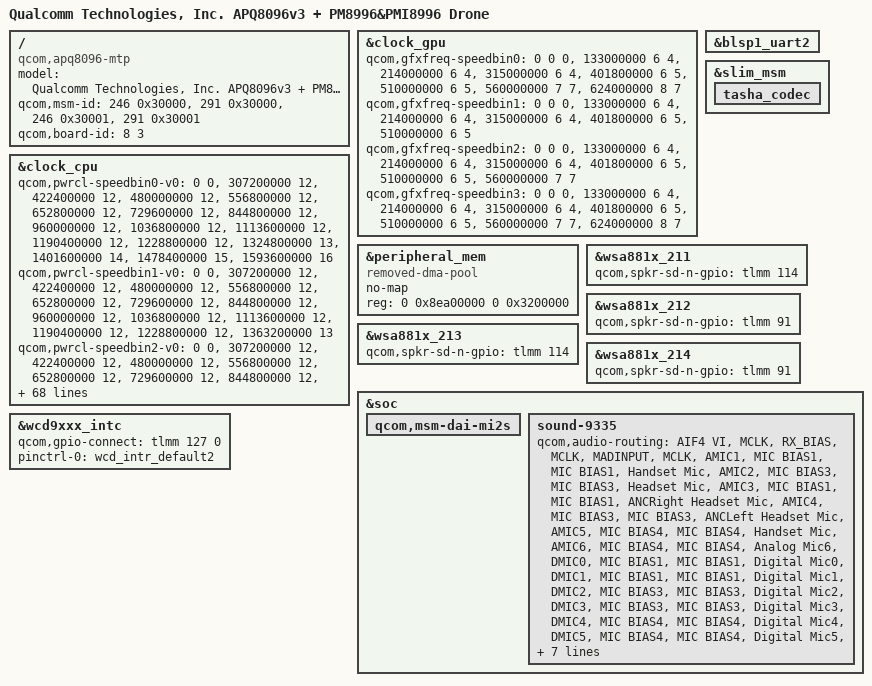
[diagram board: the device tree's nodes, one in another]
/* Copyright (c) 2016-2017, The Linux Foundation. All rights reserved.
 *
 * This program is free software; you can redistribute it and/or modify
 * it under the terms of the GNU General Public License version 2 and
 * only version 2 as published by the Free Software Foundation.
 *
 * This program is distributed in the hope that it will be useful,
 * but WITHOUT ANY WARRANTY; without even the implied warranty of
 * MERCHANTABILITY or FITNESS FOR A PARTICULAR PURPOSE.  See the
 * GNU General Public License for more details.
 */


/dts-v1/;

#include "apq8096-v3.dtsi"
#include "apq8096-drone.dtsi"
#include "msm8996-wsa881x.dtsi"

/ {
	model = "Qualcomm Technologies, Inc. APQ8096v3 + PM8996&PMI8996 Drone";
	compatible = "qcom,apq8096-mtp", "qcom,msm8996",
			"qcom,apq8096";
	qcom,msm-id = <246 0x30000>, <291 0x30000>,
			<246 0x30001>, <291 0x30001>;
	qcom,board-id = <8 3>;
};

&clock_gpu {
	qcom,gfxfreq-speedbin0 =
		<          0  0  0 >,
		<  133000000  6  4 >,
		<  214000000  6  4 >,
		<  315000000  6  4 >,
		<  401800000  6  5 >,
		<  510000000  6  5 >,
		<  560000000  7  7 >,
		<  624000000  8  7 >;
	qcom,gfxfreq-speedbin1 =
		<          0  0  0 >,
		<  133000000  6  4 >,
		<  214000000  6  4 >,
		<  315000000  6  4 >,
		<  401800000  6  5 >,
		<  510000000  6  5 >;
	qcom,gfxfreq-speedbin2 =
		<          0  0  0 >,
		<  133000000  6  4 >,
		<  214000000  6  4 >,
		<  315000000  6  4 >,
		<  401800000  6  5 >,
		<  510000000  6  5 >,
		<  560000000  7  7 >;
	qcom,gfxfreq-speedbin3 =
		<          0  0  0 >,
		<  133000000  6  4 >,
		<  214000000  6  4 >,
		<  315000000  6  4 >,
		<  401800000  6  5 >,
		<  510000000  6  5 >,
		<  560000000  7  7 >,
		<  624000000  8  7 >;
};


&clock_cpu {
	qcom,pwrcl-speedbin0-v0 =
		<          0  0 >,
		<  307200000 12 >,
		<  422400000 12 >,
		<  480000000 12 >,
		<  556800000 12 >,
		<  652800000 12 >,
		<  729600000 12 >,
		<  844800000 12 >,
		<  960000000 12 >,
		< 1036800000 12 >,
		< 1113600000 12 >,
		< 1190400000 12 >,
		< 1228800000 12 >,
		< 1324800000 13 >,
		< 1401600000 14 >,
		< 1478400000 15 >,
		< 1593600000 16 >;
	qcom,pwrcl-speedbin1-v0 =
		<          0  0 >,
		<  307200000 12 >,
		<  422400000 12 >,
		<  480000000 12 >,
		<  556800000 12 >,
		<  652800000 12 >,
		<  729600000 12 >,
		<  844800000 12 >,
		<  960000000 12 >,
		< 1036800000 12 >,
		< 1113600000 12 >,
		< 1190400000 12 >,
		< 1228800000 12 >,
		< 1363200000 13 >;
	qcom,pwrcl-speedbin2-v0 =
		<          0  0 >,
		<  307200000 12 >,
		<  422400000 12 >,
		<  480000000 12 >,
		<  556800000 12 >,
		<  652800000 12 >,
		<  729600000 12 >,
		<  844800000 12 >,
		<  960000000 12 >,
		< 1036800000 12 >,
		< 1113600000 12 >,
		< 1190400000 12 >,
		< 1228800000 12 >,
		< 1324800000 13 >,
		< 1401600000 14 >,
		< 1497600000 15 >;
	qcom,pwrcl-speedbin3-v0 =
		<          0  0 >,
		<  307200000 12 >,
		<  422400000 12 >,
		<  480000000 12 >,
		<  556800000 12 >,
		<  652800000 12 >,
		<  729600000 12 >,
		<  844800000 12 >,
		<  960000000 12 >,
		< 1036800000 12 >,
		< 1113600000 12 >,
		< 1190400000 12 >,
		< 1228800000 12 >,
		< 1324800000 13 >,
		< 1401600000 14 >,
		< 1478400000 15 >,
		< 1593600000 16 >;
	qcom,perfcl-speedbin0-v0 =
		<          0  0 >,
		<  307200000 13 >,
		<  403200000 13 >,
		<  480000000 13 >,
		<  556800000 13 >,
		<  652800000 13 >,
		<  729600000 13 >,
		<  806400000 13 >,
		<  883200000 13 >,
		<  940800000 13 >,
		< 1036800000 13 >,
		< 1113600000 13 >,
		< 1190400000 13 >,
		< 1248000000 13 >,
		< 1324800000 14 >,
		< 1401600000 15 >,
		< 1478400000 16 >,
		< 1555200000 17 >,
		< 1632000000 18 >,
		< 1708800000 19 >,
		< 1785600000 20 >,
		< 1824000000 21 >,
		< 1920000000 22 >,
		< 1996800000 23 >,
		< 2073600000 24 >,
		< 2150400000 25 >;
	qcom,perfcl-speedbin1-v0 =
		<          0  0 >,
		<  307200000 13 >,
		<  403200000 13 >,
		<  480000000 13 >,
		<  556800000 13 >,
		<  652800000 13 >,
		<  729600000 13 >,
		<  806400000 13 >,
		<  883200000 13 >,
		<  940800000 13 >,
		< 1036800000 13 >,
		< 1113600000 13 >,
		< 1190400000 13 >,
		< 1248000000 13 >,
		< 1324800000 14 >,
		< 1401600000 15 >,
		< 1478400000 16 >,
		< 1555200000 17 >,
		< 1632000000 18 >,
		< 1708800000 19 >,
		< 1785600000 20 >,
		< 1804800000 21 >;
	qcom,perfcl-speedbin2-v0 =
		<          0  0 >,
		<  307200000 13 >,
		<  403200000 13 >,
		<  480000000 13 >,
		<  556800000 13 >,
		<  652800000 13 >,
		<  729600000 13 >,
		<  806400000 13 >,
		<  883200000 13 >,
		<  940800000 13 >,
		< 1036800000 13 >,
		< 1113600000 13 >,
		< 1190400000 13 >,
		< 1248000000 13 >,
		< 1324800000 14 >,
		< 1401600000 15 >,
		< 1478400000 16 >,
		< 1555200000 17 >,
		< 1632000000 18 >,
		< 1708800000 19 >,
		< 1785600000 20 >,
		< 1804800000 21 >,
		< 1900800000 22 >;
	qcom,perfcl-speedbin3-v0 =
		<          0  0 >,
		<  307200000 13 >,
		<  403200000 13 >,
		<  480000000 13 >,
		<  556800000 13 >,
		<  652800000 13 >,
		<  729600000 13 >,
		<  806400000 13 >,
		<  883200000 13 >,
		<  940800000 13 >,
		< 1036800000 13 >,
		< 1113600000 13 >,
		< 1190400000 13 >,
		< 1248000000 13 >,
		< 1324800000 14 >,
		< 1401600000 15 >,
		< 1478400000 16 >,
		< 1555200000 17 >,
		< 1632000000 18 >,
		< 1708800000 19 >,
		< 1785600000 20 >,
		< 1804800000 21 >;
	qcom,cbf-speedbin0-v0 =
		<          0  0 >,
		<  307200000 13 >,
		<  384000000 13 >,
		<  460800000 13 >,
		<  537600000 13 >,
		<  595200000 13 >,
		<  672000000 13 >,
		<  748800000 13 >,
		<  825600000 13 >,
		<  902400000 13 >,
		<  979200000 13 >,
		< 1056000000 13 >,
		< 1132800000 13 >,
		< 1190400000 13 >,
		< 1228800000 14 >,
		< 1305600000 15 >,
		< 1382400000 16 >,
		< 1459200000 17 >,
		< 1536000000 18 >,
		< 1593600000 19 >;
	qcom,cbf-speedbin1-v0 =
		<          0  0 >,
		<  307200000 13 >,
		<  384000000 13 >,
		<  460800000 13 >,
		<  537600000 13 >,
		<  595200000 13 >,
		<  672000000 13 >,
		<  748800000 13 >,
		<  825600000 13 >,
		<  902400000 13 >,
		<  979200000 13 >,
		< 1056000000 13 >,
		< 1132800000 13 >,
		< 1190400000 13 >,
		< 1228800000 14 >,
		< 1305600000 15 >;
	qcom,cbf-speedbin2-v0 =
		<          0  0 >,
		<  307200000 13 >,
		<  384000000 13 >,
		<  460800000 13 >,
		<  537600000 13 >,
		<  595200000 13 >,
		<  672000000 13 >,
		<  748800000 13 >,
		<  825600000 13 >,
		<  902400000 13 >,
		<  979200000 13 >,
		< 1056000000 13 >,
		< 1132800000 13 >,
		< 1190400000 13 >,
		< 1228800000 14 >,
		< 1305600000 15 >;
	qcom,cbf-speedbin3-v0 =
		<          0  0 >,
		<  307200000 13 >,
		<  384000000 13 >,
		<  460800000 13 >,
		<  537600000 13 >,
		<  595200000 13 >,
		<  672000000 13 >,
		<  748800000 13 >,
		<  825600000 13 >,
		<  902400000 13 >,
		<  979200000 13 >,
		< 1056000000 13 >,
		< 1132800000 13 >,
		< 1190400000 13 >,
		< 1228800000 14 >,
		< 1305600000 15 >,
		< 1382400000 16 >,
		< 1459200000 17 >,
		< 1536000000 18 >,
		< 1593600000 19 >;
};

&blsp1_uart2 {
	status = "ok";
};

&peripheral_mem {
	compatible = "removed-dma-pool";
	no-map;
	reg = <0 0x8ea00000 0 0x3200000>;
};

&slim_msm {
	status = "ok";
	tasha_codec {
		status = "ok";
	};
};

&wsa881x_211 {
	qcom,spkr-sd-n-gpio = <&tlmm 114 0>;
};

&wsa881x_212 {
	qcom,spkr-sd-n-gpio = <&tlmm 91 0>;
};

&wsa881x_213 {
	qcom,spkr-sd-n-gpio = <&tlmm 114 0>;
};

&wsa881x_214 {
	qcom,spkr-sd-n-gpio = <&tlmm 91 0>;
};


&soc {
	qcom,msm-dai-mi2s {
		status = "ok";
	};

	sound-9335 {
		status = "ok";

		qcom,audio-routing =
			"AIF4 VI", "MCLK",
			"RX_BIAS", "MCLK",
			"MADINPUT", "MCLK",
			"AMIC1", "MIC BIAS1",
			"MIC BIAS1", "Handset Mic",
			"AMIC2", "MIC BIAS3",
			"MIC BIAS3", "Headset Mic",
			"AMIC3", "MIC BIAS1",
			"MIC BIAS1", "ANCRight Headset Mic",
			"AMIC4", "MIC BIAS3",
			"MIC BIAS3", "ANCLeft Headset Mic",
			"AMIC5", "MIC BIAS4",
			"MIC BIAS4", "Handset Mic",
			"AMIC6", "MIC BIAS4",
			"MIC BIAS4", "Analog Mic6",
			"DMIC0", "MIC BIAS1",
			"MIC BIAS1", "Digital Mic0",
			"DMIC1", "MIC BIAS1",
			"MIC BIAS1", "Digital Mic1",
			"DMIC2", "MIC BIAS3",
			"MIC BIAS3", "Digital Mic2",
			"DMIC3", "MIC BIAS3",
			"MIC BIAS3", "Digital Mic3",
			"DMIC4", "MIC BIAS4",
			"MIC BIAS4", "Digital Mic4",
			"DMIC5", "MIC BIAS4",
			"MIC BIAS4", "Digital Mic5",
			"SpkrLeft IN", "SPK1 OUT",
			"SpkrRight IN", "SPK2 OUT";

		qcom,wsa-max-devs = <2>;
		qcom,wsa-devs = <&wsa881x_211>, <&wsa881x_212>,
				<&wsa881x_213>, <&wsa881x_214>;
		qcom,wsa-aux-dev-prefix = "SpkrLeft", "SpkrRight",
					  "SpkrLeft", "SpkrRight";
	};
};

&wcd9xxx_intc {
	qcom,gpio-connect = <&tlmm 127 0>;
	pinctrl-0 = <&wcd_intr_default2>;
};
